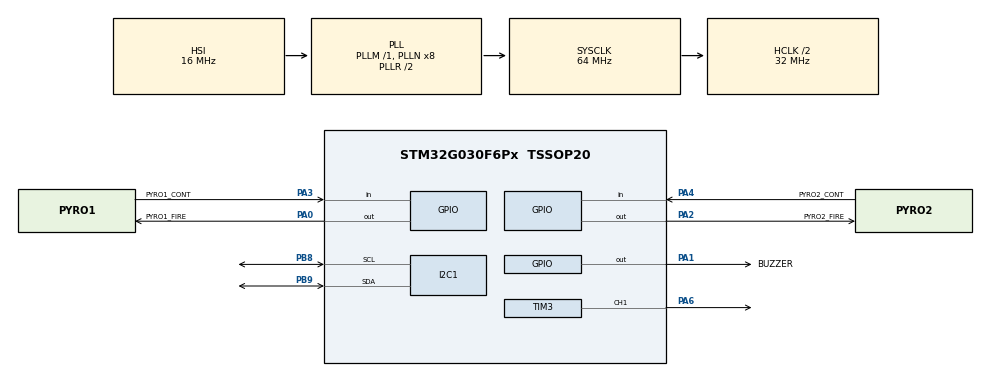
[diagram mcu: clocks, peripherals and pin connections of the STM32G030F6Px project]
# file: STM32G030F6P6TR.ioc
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I2C1.Timing=0x00B07CB4
Mcu.Family=STM32G0
Mcu.Name=STM32G030F6Px
Mcu.Package=TSSOP20
PA0.GPIO_Label=PYRO1_FIRE
PA0.Signal=GPIO_Output
PA1.GPIO_Label=BUZZER
PA1.Signal=GPIO_Output
PA13.Mode=Serial_Wire
PA13.Signal=SYS_SWDIO
PA14-BOOT0.Mode=Serial_Wire
PA14-BOOT0.Signal=SYS_SWCLK
PA14-BOOT0__PA15.StandardMode=true
PA2.GPIO_Label=PYRO2_FIRE
PA2.Signal=GPIO_Output
PA3.GPIO_Label=PYRO1_CONT
PA3.Signal=GPIO_Input
PA4.GPIO_Label=PYRO2_CONT
PA4.Signal=GPIO_Input
PA6.Signal=S_TIM3_CH1
PB0__PB1__PB2__PA8.StandardMode=true
PB3__PB4__PB5__PB6.StandardMode=true
PB7__PB8.StandardMode=true
PB8.Mode=I2C
PB8.Signal=I2C1_SCL
PB9.Mode=I2C
PB9.Signal=I2C1_SDA
PC14-OSC32_IN\ (PC14)__PB9.StandardMode=true
ProjectManager.HeapSize=0x200
ProjectManager.StackSize=0x400
ProjectManager.TargetToolchain=STM32CubeIDE
RCC.ADCFreq_Value=64000000
RCC.AHBCLKDivider=RCC_SYSCLK_DIV2
RCC.AHBFreq_Value=32000000
RCC.CortexFreq_Value=32000000
RCC.EXTERNAL_CLOCK_VALUE=12288000
RCC.HCLKFreq_Value=32000000
RCC.HSE_VALUE=8000000
RCC.HSI_VALUE=16000000
RCC.LSE_VALUE=32768
RCC.SYSCLKFreq_VALUE=64000000
RCC.SYSCLKSource=RCC_SYSCLKSOURCE_PLLCLK
RCC.VCOOutputFreq_Value=128000000
SH.S_TIM3_CH1.0=TIM3_CH1,PWM Generation1 CH1
TIM3.Channel-PWM\ Generation1\ CH1=TIM_CHANNEL_1
TIM3.Period=249
TIM3.Prescaler=32
TIM3.Pulse-PWM\ Generation1\ CH1=125
VP_TIM3_VS_ClockSourceINT.Mode=Internal
board=custom

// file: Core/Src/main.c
/* USER CODE BEGIN Header */
/**
  ******************************************************************************
  * @file           : main.c
  * @brief          : Main program body
  ******************************************************************************
  * @attention
  *
  * Copyright (c) 2024 STMicroelectronics.
  * All rights reserved.
  *
  * This software is licensed under terms that can be found in the LICENSE file
  * in the root directory of this software component.
  * If no LICENSE file comes with this software, it is provided AS-IS.
  *
  ******************************************************************************
  */
/* USER CODE END Header */
#include "main.h"

/* USER CODE BEGIN Includes */
#include <stdio.h>
#include "ms5607.h"
#include "buzzer.h"
/* USER CODE END Includes */

I2C_HandleTypeDef hi2c1;

TIM_HandleTypeDef htim3;

/* USER CODE BEGIN PV */
ms5607_t ms5607_sensor;
/* USER CODE END PV */

void SystemClock_Config(void);
static void MX_GPIO_Init(void);
static void MX_I2C1_Init(void);
static void MX_TIM3_Init(void);

int main(void)
{

  /* MCU Configuration--------------------------------------------------------*/

  /* Reset of all peripherals, Initializes the Flash interface and the Systick. */
  HAL_Init();

  /* Configure the system clock */
  SystemClock_Config();

  /* Initialize all configured peripherals */
  MX_GPIO_Init();
  MX_I2C1_Init();
  MX_TIM3_Init();
  /* USER CODE BEGIN 2 */
  if (TEST_MODE) {

  }
  AltimeterStateMachine();

  /* USER CODE END 2 */

  /* Infinite loop */
  while (1)
  {
  }
}

void SystemClock_Config(void)
{
  RCC_OscInitTypeDef RCC_OscInitStruct = {0};
  RCC_ClkInitTypeDef RCC_ClkInitStruct = {0};

  /** Configure the main internal regulator output voltage
  */
  HAL_PWREx_ControlVoltageScaling(PWR_REGULATOR_VOLTAGE_SCALE1);

  /** Initializes the RCC Oscillators according to the specified parameters
  * in the RCC_OscInitTypeDef structure.
  */
  RCC_OscInitStruct.OscillatorType = RCC_OSCILLATORTYPE_HSI;
  RCC_OscInitStruct.HSIState = RCC_HSI_ON;
  RCC_OscInitStruct.HSIDiv = RCC_HSI_DIV1;
  RCC_OscInitStruct.HSICalibrationValue = RCC_HSICALIBRATION_DEFAULT;
  RCC_OscInitStruct.PLL.PLLState = RCC_PLL_ON;
  RCC_OscInitStruct.PLL.PLLSource = RCC_PLLSOURCE_HSI;
  RCC_OscInitStruct.PLL.PLLM = RCC_PLLM_DIV1;
  RCC_OscInitStruct.PLL.PLLN = 8;
  RCC_OscInitStruct.PLL.PLLP = RCC_PLLP_DIV2;
  RCC_OscInitStruct.PLL.PLLR = RCC_PLLR_DIV2;
  if (HAL_RCC_OscConfig(&RCC_OscInitStruct) != HAL_OK)
  {
    Error_Handler();
  }

  /** Initializes the CPU, AHB and APB buses clocks
  */
  RCC_ClkInitStruct.ClockType = RCC_CLOCKTYPE_HCLK|RCC_CLOCKTYPE_SYSCLK
                              |RCC_CLOCKTYPE_PCLK1;
  RCC_ClkInitStruct.SYSCLKSource = RCC_SYSCLKSOURCE_PLLCLK;
  RCC_ClkInitStruct.AHBCLKDivider = RCC_SYSCLK_DIV2;
  RCC_ClkInitStruct.APB1CLKDivider = RCC_HCLK_DIV1;

  if (HAL_RCC_ClockConfig(&RCC_ClkInitStruct, FLASH_LATENCY_1) != HAL_OK)
  {
    Error_Handler();
  }
}

static void MX_I2C1_Init(void)
{

  hi2c1.Instance = I2C1;
  hi2c1.Init.Timing = 0x00B07CB4;
  hi2c1.Init.OwnAddress1 = 0;
  hi2c1.Init.AddressingMode = I2C_ADDRESSINGMODE_7BIT;
  hi2c1.Init.DualAddressMode = I2C_DUALADDRESS_DISABLE;
  hi2c1.Init.OwnAddress2 = 0;
  hi2c1.Init.OwnAddress2Masks = I2C_OA2_NOMASK;
  hi2c1.Init.GeneralCallMode = I2C_GENERALCALL_DISABLE;
  hi2c1.Init.NoStretchMode = I2C_NOSTRETCH_DISABLE;
  if (HAL_I2C_Init(&hi2c1) != HAL_OK)
  {
    Error_Handler();
  }

  /** Configure Analogue filter
  */
  if (HAL_I2CEx_ConfigAnalogFilter(&hi2c1, I2C_ANALOGFILTER_ENABLE) != HAL_OK)
  {
    Error_Handler();
  }

  /** Configure Digital filter
  */
  if (HAL_I2CEx_ConfigDigitalFilter(&hi2c1, 0) != HAL_OK)
  {
    Error_Handler();
  }

}

static void MX_TIM3_Init(void)
{

  TIM_ClockConfigTypeDef sClockSourceConfig = {0};
  TIM_MasterConfigTypeDef sMasterConfig = {0};
  TIM_OC_InitTypeDef sConfigOC = {0};

  htim3.Instance = TIM3;
  htim3.Init.Prescaler = 32;
  htim3.Init.CounterMode = TIM_COUNTERMODE_UP;
  htim3.Init.Period = 249;
  htim3.Init.ClockDivision = TIM_CLOCKDIVISION_DIV1;
  htim3.Init.AutoReloadPreload = TIM_AUTORELOAD_PRELOAD_DISABLE;
  if (HAL_TIM_Base_Init(&htim3) != HAL_OK)
  {
    Error_Handler();
  }
  sClockSourceConfig.ClockSource = TIM_CLOCKSOURCE_INTERNAL;
  if (HAL_TIM_ConfigClockSource(&htim3, &sClockSourceConfig) != HAL_OK)
  {
    Error_Handler();
  }
  if (HAL_TIM_PWM_Init(&htim3) != HAL_OK)
  {
    Error_Handler();
  }
  sMasterConfig.MasterOutputTrigger = TIM_TRGO_RESET;
  sMasterConfig.MasterSlaveMode = TIM_MASTERSLAVEMODE_DISABLE;
  if (HAL_TIMEx_MasterConfigSynchronization(&htim3, &sMasterConfig) != HAL_OK)
  {
    Error_Handler();
  }
  sConfigOC.OCMode = TIM_OCMODE_PWM1;
  sConfigOC.Pulse = 125;
  sConfigOC.OCPolarity = TIM_OCPOLARITY_HIGH;
  sConfigOC.OCFastMode = TIM_OCFAST_DISABLE;
  if (HAL_TIM_PWM_ConfigChannel(&htim3, &sConfigOC, TIM_CHANNEL_1) != HAL_OK)
  {
    Error_Handler();
  }
  HAL_TIM_MspPostInit(&htim3);

}

static void MX_GPIO_Init(void)
{
  GPIO_InitTypeDef GPIO_InitStruct = {0};

  /* GPIO Ports Clock Enable */
  __HAL_RCC_GPIOB_CLK_ENABLE();
  __HAL_RCC_GPIOA_CLK_ENABLE();

  /*Configure GPIO pin Output Level */
  HAL_GPIO_WritePin(GPIOA, PYRO1_FIRE_Pin|BUZZER_Pin|PYRO2_FIRE_Pin, GPIO_PIN_RESET);

  /*Configure GPIO pins : PYRO1_FIRE_Pin BUZZER_Pin PYRO2_FIRE_Pin */
  GPIO_InitStruct.Pin = PYRO1_FIRE_Pin|BUZZER_Pin|PYRO2_FIRE_Pin;
  GPIO_InitStruct.Mode = GPIO_MODE_OUTPUT_PP;
  GPIO_InitStruct.Pull = GPIO_NOPULL;
  GPIO_InitStruct.Speed = GPIO_SPEED_FREQ_LOW;
  HAL_GPIO_Init(GPIOA, &GPIO_InitStruct);

  /*Configure GPIO pins : PYRO1_CONT_Pin PYRO2_CONT_Pin */
  GPIO_InitStruct.Pin = PYRO1_CONT_Pin|PYRO2_CONT_Pin;
  GPIO_InitStruct.Mode = GPIO_MODE_INPUT;
  GPIO_InitStruct.Pull = GPIO_NOPULL;
  HAL_GPIO_Init(GPIOA, &GPIO_InitStruct);

}

void Error_Handler(void)
{
  /* USER CODE BEGIN Error_Handler_Debug */
  /* User can add his own implementation to report the HAL error return state */
  __disable_irq();
  while (1)
  {
	  Buzzer_Start(100);
	  HAL_Delay(100);
	  Buzzer_Update(); // Ensure buzzer stops
	  HAL_Delay(100);
  }
  /* USER CODE END Error_Handler_Debug */
}
